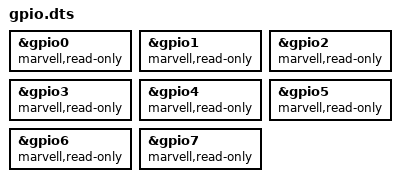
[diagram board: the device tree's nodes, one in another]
// SPDX-License-Identifier: GPL-2.0
/*
 * gpio variant: the base board with GPIO banks A-H registered read-only
 * (marvell,read-only): no pin-mux change, no output or direction change.
 */
#include "88pa6170-dp200.dts"

&gpio0 { status = "okay"; marvell,read-only; };
&gpio1 { status = "okay"; marvell,read-only; };
&gpio2 { status = "okay"; marvell,read-only; };
&gpio3 { status = "okay"; marvell,read-only; };
&gpio4 { status = "okay"; marvell,read-only; };
&gpio5 { status = "okay"; marvell,read-only; };
&gpio6 { status = "okay"; marvell,read-only; };
&gpio7 { status = "okay"; marvell,read-only; };
